# STM32F768 register map
File version: 2.0
CPU: CM7 r0p1, little endian, MPU, FPU, 4 interrupt priority bits
Registers are 32-bit, read-write, reset 0x0 unless marked. A register's access mark holds for its fields unless they carry their own. Offsets are from the block's base; [hi:lo] are bit positions; {n}, {i} and the like mark numbered series.

## ADC_Common — Common ADC registers
Base 0x40012300
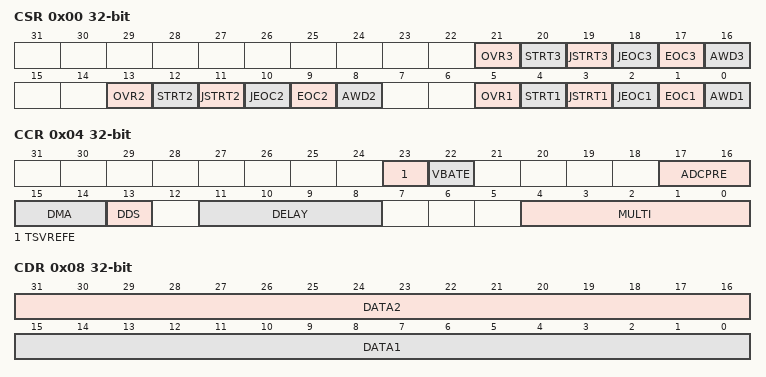
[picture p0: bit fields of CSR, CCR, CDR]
0x00 CSR ro — ADC Common status register
  [21] OVR3, [20] STRT3, [19] JSTRT3, [18] JEOC3, [17] EOC3, [16] AWD3, [13] OVR2, [12] STRT2, [11] JSTRT2, [10] JEOC2, [9] EOC2, [8] AWD2, [5] OVR1, [4] STRT1, [3] JSTRT1, [2] JEOC1, [1] EOC1, [0] AWD1
0x04 CCR — ADC common control register
  [23] TSVREFE, [22] VBATE, [17:16] ADCPRE, [15:14] DMA, [13] DDS, [11:8] DELAY, [4:0] MULTI
0x08 CDR ro — ADC common regular data register for dual and triple modes
  [31:16] DATA2, [15:0] DATA1

## DBG — Debug support
Base 0xE0042000
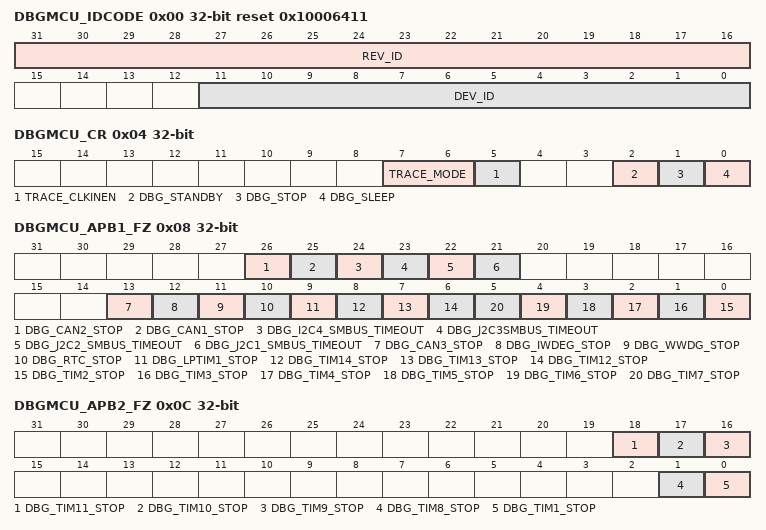
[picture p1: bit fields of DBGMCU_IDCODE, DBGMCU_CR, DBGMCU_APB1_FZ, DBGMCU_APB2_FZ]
0x00 DBGMCU_IDCODE ro reset 0x10006411 — IDCODE
  [31:16] REV_ID, [11:0] DEV_ID
0x04 DBGMCU_CR — Control Register
  [7:6] TRACE_MODE, [5] TRACE_CLKINEN, [2] DBG_STANDBY, [1] DBG_STOP, [0] DBG_SLEEP
0x08 DBGMCU_APB1_FZ — Debug MCU APB1 Freeze registe
  [26] DBG_CAN2_STOP, [25] DBG_CAN1_STOP, [24] DBG_I2C4_SMBUS_TIMEOUT, [23] DBG_J2C3SMBUS_TIMEOUT, [22] DBG_J2C2_SMBUS_TIMEOUT, [21] DBG_J2C1_SMBUS_TIMEOUT, [13] DBG_CAN3_STOP, [12] DBG_IWDEG_STOP, [11] DBG_WWDG_STOP, [10] DBG_RTC_STOP, [9] DBG_LPTIM1_STOP, [8] DBG_TIM14_STOP, [7] DBG_TIM13_STOP, [6] DBG_TIM12_STOP, [n-2] DBG_TIM{n}_STOP (n=2..7)
0x0C DBGMCU_APB2_FZ — Debug MCU APB2 Freeze registe
  [18] DBG_TIM11_STOP — TIM11 counter stopped when core is halted
  [17] DBG_TIM10_STOP — TIM10 counter stopped when core is halted
  [16] DBG_TIM9_STOP — TIM9 counter stopped when core is halted
  [1] DBG_TIM8_STOP — TIM8 counter stopped when core is halted
  [0] DBG_TIM1_STOP — TIM1 counter stopped when core is halted

## DAC — Digital-to-analog converter
Base 0x40007400
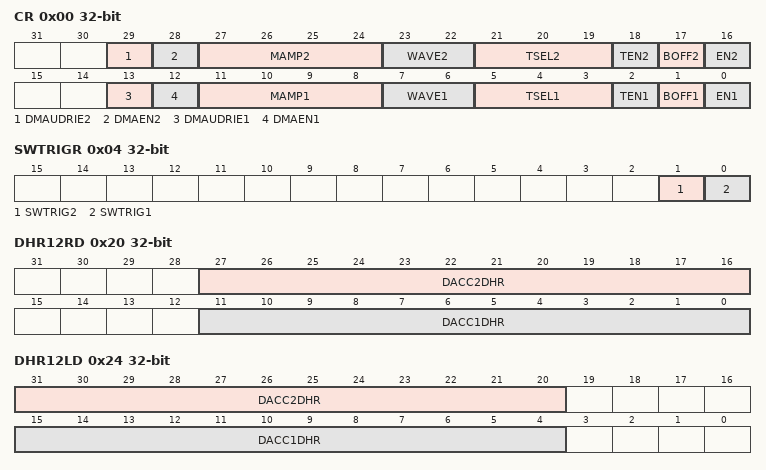
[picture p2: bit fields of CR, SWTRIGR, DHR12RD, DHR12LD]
0x00 CR — control register
  [29] DMAUDRIE2 — DAC channel2 DMA underrun interrupt enable
  [28] DMAEN2 — DAC channel2 DMA enable
  [27:24] MAMP2 — DAC channel2 mask/amplitude selector
  [23:22] WAVE2 — DAC channel2 noise/triangle wave generation enable
  [21:19] TSEL2 — DAC channel2 trigger selection
  [18] TEN2 — DAC channel2 trigger enable
  [17] BOFF2 — DAC channel2 output buffer disable
  [16] EN2 — DAC channel2 enable
  [13] DMAUDRIE1 — DAC channel1 DMA Underrun Interrupt enable
  [12] DMAEN1 — DAC channel1 DMA enable
  [11:8] MAMP1 — DAC channel1 mask/amplitude selector
  [7:6] WAVE1 — DAC channel1 noise/triangle wave generation enable
  [5:3] TSEL1 — DAC channel1 trigger selection
  [2] TEN1 — DAC channel1 trigger enable
  [1] BOFF1 — DAC channel1 output buffer disable
  [0] EN1 — DAC channel1 enable
0x04 SWTRIGR wo — software trigger register
  [1] SWTRIG2 — DAC channel2 software trigger
  [0] SWTRIG1 — DAC channel1 software trigger
0x08 DHR12R1 — channel1 12-bit right-aligned data holding register
  [11:0] DACC1DHR — DAC channel1 12-bit right-aligned data
0x0C DHR12L1 — channel1 12-bit left aligned data holding register
  [15:4] DACC1DHR — DAC channel1 12-bit left-aligned data
0x10 DHR8R1 — channel1 8-bit right aligned data holding register
  [7:0] DACC1DHR — DAC channel1 8-bit right-aligned data
0x14 DHR12R2 — channel2 12-bit right aligned data holding register
  [11:0] DACC2DHR — DAC channel2 12-bit right-aligned data
0x18 DHR12L2 — channel2 12-bit left aligned data holding register
  [15:4] DACC2DHR — DAC channel2 12-bit left-aligned data
0x1C DHR8R2 — channel2 8-bit right-aligned data holding register
  [7:0] DACC2DHR — DAC channel2 8-bit right-aligned data
0x20 DHR12RD — Dual DAC 12-bit right-aligned data holding register
  [27:16] DACC2DHR — DAC channel2 12-bit right-aligned data
  [11:0] DACC1DHR — DAC channel1 12-bit right-aligned data
0x24 DHR12LD — DUAL DAC 12-bit left aligned data holding register
  [31:20] DACC2DHR — DAC channel2 12-bit left-aligned data
  [15:4] DACC1DHR — DAC channel1 12-bit left-aligned data
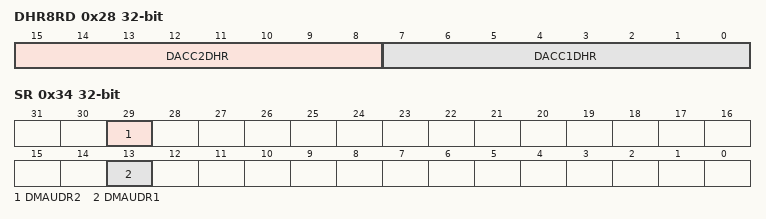
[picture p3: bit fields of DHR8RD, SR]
0x28 DHR8RD — DUAL DAC 8-bit right aligned data holding register
  [15:8] DACC2DHR — DAC channel2 8-bit right-aligned data
  [7:0] DACC1DHR — DAC channel1 8-bit right-aligned data
0x2C DOR1 ro — channel1 data output register
  [11:0] DACC1DOR — DAC channel1 data output
0x30 DOR2 ro — channel2 data output register
  [11:0] DACC2DOR — DAC channel2 data output
0x34 SR — status register
  [29] DMAUDR2 — DAC channel2 DMA underrun flag
  [13] DMAUDR1 — DAC channel1 DMA underrun flag

## Notices in the file
Copyright (c) 2025 STMicroelectronics.
SPDX-License-Identifier: Apache-2.0
Licensed under the Apache License, Version 2.0 (the "License");
you may not use this file except in compliance with the License.
You may obtain a copy of the License at
http://www.apache.org/licenses/LICENSE-2.0
Unless required by applicable law or agreed to in writing, software
distributed under the License is distributed on an "AS IS" BASIS,
WITHOUT WARRANTIES OR CONDITIONS OF ANY KIND, either express or implied.
See the License for the specific language governing permissions and
limitations under the License.
